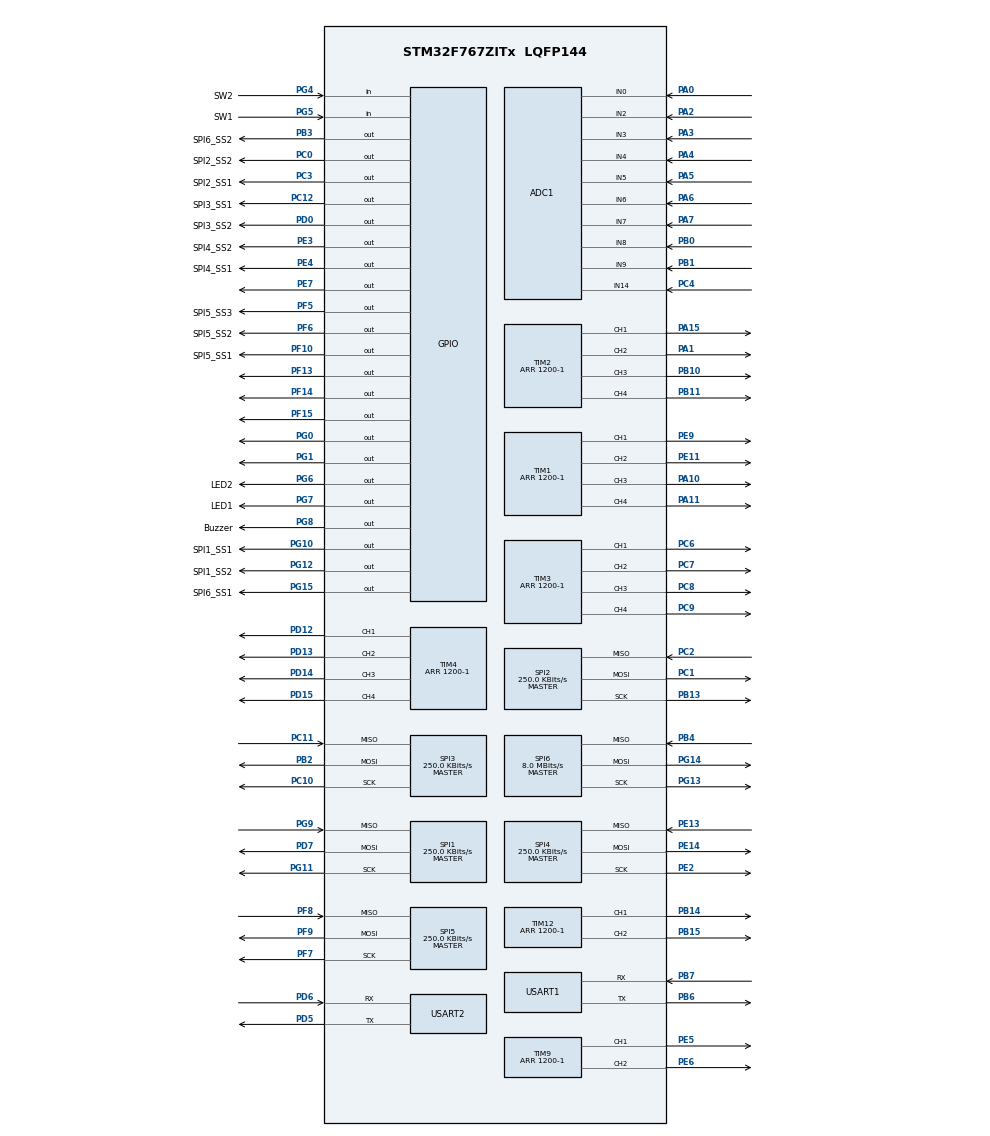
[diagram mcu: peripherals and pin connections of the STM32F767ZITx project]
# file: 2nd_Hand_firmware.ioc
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ADC1.Channel-0\#ChannelRegularConversion=ADC_CHANNEL_0
ADC1.NbrOfConversionFlag=1
ADC1.Rank-0\#ChannelRegularConversion=1
ADC1.SamplingTime-0\#ChannelRegularConversion=ADC_SAMPLETIME_3CYCLES
ADC1.master=1
CORTEX_M7.default_mode_Activation=1
Mcu.Family=STM32F7
Mcu.Name=STM32F767ZITx
Mcu.Package=LQFP144
NVIC.PriorityGroup=NVIC_PRIORITYGROUP_4
NVIC.TIM5_IRQn=true\:0\:0\:false\:false\:true\:true\:true\:true
NVIC.USART1_IRQn=true\:0\:0\:false\:false\:true\:true\:true\:true
PA0/WKUP.Signal=ADCx_IN0
PA1.Signal=S_TIM2_CH2
PA10.Signal=S_TIM1_CH3
PA11.Signal=S_TIM1_CH4
PA13.Mode=Serial_Wire
PA13.Signal=SYS_JTMS-SWDIO
PA14.Mode=Serial_Wire
PA14.Signal=SYS_JTCK-SWCLK
PA15.Signal=S_TIM2_CH1_ETR
PA2.Signal=ADCx_IN2
PA3.Signal=ADCx_IN3
PA4.Signal=ADCx_IN4
PA5.Signal=ADCx_IN5
PA6.Signal=ADCx_IN6
PA7.Signal=ADCx_IN7
PB0.Signal=ADCx_IN8
PB1.Signal=ADCx_IN9
PB10.Signal=S_TIM2_CH3
PB11.Signal=S_TIM2_CH4
PB13.Mode=Full_Duplex_Master
PB13.Signal=SPI2_SCK
PB14.Signal=S_TIM12_CH1
PB15.Signal=S_TIM12_CH2
PB2.Mode=Full_Duplex_Master
PB2.Signal=SPI3_MOSI
PB3.GPIO_Label=SPI6_SS2
PB3.GPIO_PuPd=GPIO_PULLUP
PB3.Signal=GPIO_Output
PB4.Mode=Full_Duplex_Master
PB4.Signal=SPI6_MISO
PB6.Mode=Asynchronous
PB6.Signal=USART1_TX
PB7.Mode=Asynchronous
PB7.Signal=USART1_RX
PC0.GPIO_Label=SPI2_SS2
PC0.GPIO_PuPd=GPIO_PULLUP
PC0.Signal=GPIO_Output
PC1.Mode=Full_Duplex_Master
PC1.Signal=SPI2_MOSI
PC10.Mode=Full_Duplex_Master
PC10.Signal=SPI3_SCK
PC11.Mode=Full_Duplex_Master
PC11.Signal=SPI3_MISO
PC12.GPIO_Label=SPI3_SS1
PC12.GPIO_PuPd=GPIO_PULLUP
PC12.Signal=GPIO_Output
PC14/OSC32_IN.Mode=LSE-External-Oscillator
PC14/OSC32_IN.Signal=RCC_OSC32_IN
PC15/OSC32_OUT.Mode=LSE-External-Oscillator
PC15/OSC32_OUT.Signal=RCC_OSC32_OUT
PC2.Mode=Full_Duplex_Master
PC2.Signal=SPI2_MISO
PC3.GPIO_Label=SPI2_SS1
PC3.GPIO_PuPd=GPIO_PULLUP
PC3.Signal=GPIO_Output
PC4.Signal=ADCx_IN14
PC6.Signal=S_TIM3_CH1
PC7.Signal=S_TIM3_CH2
PC8.Signal=S_TIM3_CH3
PC9.Signal=S_TIM3_CH4
PD0.GPIO_Label=SPI3_SS2
PD0.GPIO_PuPd=GPIO_PULLUP
PD0.Signal=GPIO_Output
PD12.Signal=S_TIM4_CH1
PD13.Signal=S_TIM4_CH2
PD14.Signal=S_TIM4_CH3
PD15.Signal=S_TIM4_CH4
PD5.Mode=Asynchronous
PD5.Signal=USART2_TX
PD6.Mode=Asynchronous
PD6.Signal=USART2_RX
PD7.Mode=Full_Duplex_Master
PD7.Signal=SPI1_MOSI
PE11.Signal=S_TIM1_CH2
PE13.Mode=Full_Duplex_Master
PE13.Signal=SPI4_MISO
PE14.Mode=Full_Duplex_Master
PE14.Signal=SPI4_MOSI
PE2.Mode=Full_Duplex_Master
PE2.Signal=SPI4_SCK
PE3.GPIO_Label=SPI4_SS2
PE3.GPIO_PuPd=GPIO_PULLUP
PE3.Signal=GPIO_Output
PE4.GPIO_Label=SPI4_SS1
PE4.GPIO_PuPd=GPIO_PULLUP
PE4.Signal=GPIO_Output
PE5.Signal=S_TIM9_CH1
PE6.Signal=S_TIM9_CH2
PE7.Signal=GPIO_Output
PE9.Signal=S_TIM1_CH1
PF10.GPIO_Label=SPI5_SS1
PF10.GPIO_PuPd=GPIO_PULLUP
PF10.Signal=GPIO_Output
PF13.Signal=GPIO_Output
PF14.Signal=GPIO_Output
PF15.Signal=GPIO_Output
PF5.GPIO_Label=SPI5_SS3
PF5.GPIO_PuPd=GPIO_PULLUP
PF5.Signal=GPIO_Output
PF6.GPIO_Label=SPI5_SS2
PF6.GPIO_PuPd=GPIO_PULLUP
PF6.Signal=GPIO_Output
PF7.Mode=Full_Duplex_Master
PF7.Signal=SPI5_SCK
PF8.Mode=Full_Duplex_Master
PF8.Signal=SPI5_MISO
PF9.Mode=Full_Duplex_Master
PF9.Signal=SPI5_MOSI
PG0.Signal=GPIO_Output
PG1.Signal=GPIO_Output
PG10.GPIO_Label=SPI1_SS1
PG10.GPIO_PuPd=GPIO_PULLUP
PG10.Signal=GPIO_Output
PG11.Mode=Full_Duplex_Master
PG11.Signal=SPI1_SCK
PG12.GPIO_Label=SPI1_SS2
PG12.GPIO_PuPd=GPIO_PULLUP
PG12.Signal=GPIO_Output
PG13.Mode=Full_Duplex_Master
PG13.Signal=SPI6_SCK
PG14.Mode=Full_Duplex_Master
PG14.Signal=SPI6_MOSI
PG15.GPIO_Label=SPI6_SS1
PG15.GPIO_PuPd=GPIO_PULLUP
PG15.Signal=GPIO_Output
PG4.GPIO_Label=SW2
PG4.GPIO_PuPd=GPIO_PULLUP
PG4.Signal=GPIO_Input
PG5.GPIO_Label=SW1
PG5.GPIO_PuPd=GPIO_PULLUP
PG5.Signal=GPIO_Input
PG6.GPIO_Label=LED2
PG6.Signal=GPIO_Output
PG7.GPIO_Label=LED1
PG7.Signal=GPIO_Output
PG8.GPIO_Label=Buzzer
PG8.Signal=GPIO_Output
PG9.Mode=Full_Duplex_Master
PG9.Signal=SPI1_MISO
PH0/OSC_IN.Mode=HSE-External-Oscillator
PH0/OSC_IN.Signal=RCC_OSC_IN
PH1/OSC_OUT.Mode=HSE-External-Oscillator
PH1/OSC_OUT.Signal=RCC_OSC_OUT
ProjectManager.HeapSize=0x200
ProjectManager.StackSize=0x400
ProjectManager.TargetToolchain=CMake
RCC.HSE_VALUE=25000000
RCC.HSI_VALUE=16000000
RCC.USBFreq_Value=96000000
RCC.VCOOutputFreq_Value=192000000
SH.ADCx_IN0.0=ADC1_IN0,IN0
SH.ADCx_IN14.0=ADC1_IN14,IN14
SH.ADCx_IN2.0=ADC1_IN2,IN2
SH.ADCx_IN3.0=ADC1_IN3,IN3
SH.ADCx_IN4.0=ADC1_IN4,IN4
SH.ADCx_IN5.0=ADC1_IN5,IN5
SH.ADCx_IN6.0=ADC1_IN6,IN6
SH.ADCx_IN7.0=ADC1_IN7,IN7
SH.ADCx_IN8.0=ADC1_IN8,IN8
SH.ADCx_IN9.0=ADC1_IN9,IN9
SH.S_TIM12_CH1.0=TIM12_CH1,PWM Generation1 CH1
SH.S_TIM12_CH2.0=TIM12_CH2,PWM Generation2 CH2
SH.S_TIM1_CH1.0=TIM1_CH1,PWM Generation1 CH1
SH.S_TIM1_CH2.0=TIM1_CH2,PWM Generation2 CH2
SH.S_TIM1_CH3.0=TIM1_CH3,PWM Generation3 CH3
SH.S_TIM1_CH4.0=TIM1_CH4,PWM Generation4 CH4
SH.S_TIM2_CH1_ETR.0=TIM2_CH1,PWM Generation1 CH1
SH.S_TIM2_CH2.0=TIM2_CH2,PWM Generation2 CH2
SH.S_TIM2_CH3.0=TIM2_CH3,PWM Generation3 CH3
SH.S_TIM2_CH4.0=TIM2_CH4,PWM Generation4 CH4
SH.S_TIM3_CH1.0=TIM3_CH1,PWM Generation1 CH1
SH.S_TIM3_CH2.0=TIM3_CH2,PWM Generation2 CH2
SH.S_TIM3_CH3.0=TIM3_CH3,PWM Generation3 CH3
SH.S_TIM3_CH4.0=TIM3_CH4,PWM Generation4 CH4
SH.S_TIM4_CH1.0=TIM4_CH1,PWM Generation1 CH1
SH.S_TIM4_CH2.0=TIM4_CH2,PWM Generation2 CH2
SH.S_TIM4_CH3.0=TIM4_CH3,PWM Generation3 CH3
SH.S_TIM4_CH4.0=TIM4_CH4,PWM Generation4 CH4
SH.S_TIM9_CH1.0=TIM9_CH1,PWM Generation1 CH1
SH.S_TIM9_CH2.0=TIM9_CH2,PWM Generation2 CH2
SPI1.BaudRatePrescaler=SPI_BAUDRATEPRESCALER_64
SPI1.CLKPhase=SPI_PHASE_1EDGE
SPI1.CalculateBaudRate=250.0 KBits/s
SPI1.DataSize=SPI_DATASIZE_8BIT
SPI1.Direction=SPI_DIRECTION_2LINES
SPI1.Mode=SPI_MODE_MASTER
SPI1.NSSPMode=SPI_NSS_PULSE_DISABLE
SPI1.VirtualType=VM_MASTER
SPI2.BaudRatePrescaler=SPI_BAUDRATEPRESCALER_64
SPI2.CLKPhase=SPI_PHASE_1EDGE
SPI2.CalculateBaudRate=250.0 KBits/s
SPI2.DataSize=SPI_DATASIZE_8BIT
SPI2.Direction=SPI_DIRECTION_2LINES
SPI2.Mode=SPI_MODE_MASTER
SPI2.NSSPMode=SPI_NSS_PULSE_DISABLE
SPI2.VirtualType=VM_MASTER
SPI3.BaudRatePrescaler=SPI_BAUDRATEPRESCALER_64
SPI3.CLKPhase=SPI_PHASE_1EDGE
SPI3.CalculateBaudRate=250.0 KBits/s
SPI3.DataSize=SPI_DATASIZE_8BIT
SPI3.Direction=SPI_DIRECTION_2LINES
SPI3.Mode=SPI_MODE_MASTER
SPI3.NSSPMode=SPI_NSS_PULSE_DISABLE
SPI3.VirtualType=VM_MASTER
SPI4.BaudRatePrescaler=SPI_BAUDRATEPRESCALER_64
SPI4.CLKPhase=SPI_PHASE_2EDGE
SPI4.CalculateBaudRate=250.0 KBits/s
SPI4.DataSize=SPI_DATASIZE_16BIT
SPI4.Direction=SPI_DIRECTION_2LINES
SPI4.Mode=SPI_MODE_MASTER
SPI4.VirtualType=VM_MASTER
SPI5.BaudRatePrescaler=SPI_BAUDRATEPRESCALER_64
SPI5.CLKPhase=SPI_PHASE_1EDGE
SPI5.CalculateBaudRate=250.0 KBits/s
SPI5.DataSize=SPI_DATASIZE_8BIT
SPI5.Direction=SPI_DIRECTION_2LINES
SPI5.Mode=SPI_MODE_MASTER
SPI5.NSSPMode=SPI_NSS_PULSE_DISABLE
SPI5.VirtualType=VM_MASTER
SPI6.BaudRatePrescaler=SPI_BAUDRATEPRESCALER_2
SPI6.CalculateBaudRate=8.0 MBits/s
SPI6.DataSize=SPI_DATASIZE_4BIT
SPI6.Direction=SPI_DIRECTION_2LINES
SPI6.Mode=SPI_MODE_MASTER
SPI6.VirtualType=VM_MASTER
TIM1.Channel-PWM\ Generation1\ CH1=TIM_CHANNEL_1
TIM1.Channel-PWM\ Generation2\ CH2=TIM_CHANNEL_2
TIM1.Channel-PWM\ Generation3\ CH3=TIM_CHANNEL_3
TIM1.Channel-PWM\ Generation4\ CH4=TIM_CHANNEL_4
TIM1.Period=1200-1
TIM12.Channel-PWM\ Generation1\ CH1=TIM_CHANNEL_1
TIM12.Channel-PWM\ Generation2\ CH2=TIM_CHANNEL_2
TIM12.Period=1200-1
TIM2.Channel-PWM\ Generation1\ CH1=TIM_CHANNEL_1
TIM2.Channel-PWM\ Generation2\ CH2=TIM_CHANNEL_2
TIM2.Channel-PWM\ Generation3\ CH3=TIM_CHANNEL_3
TIM2.Channel-PWM\ Generation4\ CH4=TIM_CHANNEL_4
TIM2.Period=1200-1
TIM3.Channel-PWM\ Generation1\ CH1=TIM_CHANNEL_1
TIM3.Channel-PWM\ Generation2\ CH2=TIM_CHANNEL_2
TIM3.Channel-PWM\ Generation3\ CH3=TIM_CHANNEL_3
TIM3.Channel-PWM\ Generation4\ CH4=TIM_CHANNEL_4
TIM3.Period=1200-1
TIM4.Channel-PWM\ Generation1\ CH1=TIM_CHANNEL_1
TIM4.Channel-PWM\ Generation2\ CH2=TIM_CHANNEL_2
TIM4.Channel-PWM\ Generation3\ CH3=TIM_CHANNEL_3
TIM4.Channel-PWM\ Generation4\ CH4=TIM_CHANNEL_4
TIM4.Period=1200-1
TIM5.Period=10000-1
TIM5.Prescaler=96
TIM9.Channel-PWM\ Generation1\ CH1=TIM_CHANNEL_1
TIM9.Channel-PWM\ Generation2\ CH2=TIM_CHANNEL_2
TIM9.Period=1200-1
USART1.VirtualMode-Asynchronous=VM_ASYNC
USART2.VirtualMode-Asynchronous=VM_ASYNC
VP_TIM12_VS_ClockSourceINT.Mode=Internal
VP_TIM1_VS_ClockSourceINT.Mode=Internal
VP_TIM2_VS_ClockSourceINT.Mode=Internal
VP_TIM3_VS_ClockSourceINT.Mode=Internal
VP_TIM4_VS_ClockSourceINT.Mode=Internal
VP_TIM5_VS_ClockSourceINT.Mode=Internal
VP_TIM9_VS_ClockSourceINT.Mode=Internal
board=custom

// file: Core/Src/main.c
/* USER CODE BEGIN Header */
/**
  ******************************************************************************
  * @file           : main.c
  * @brief          : Main program body
  ******************************************************************************
  * @attention
  *
  * Copyright (c) 2025 STMicroelectronics.
  * All rights reserved.
  *
  * This software is licensed under terms that can be found in the LICENSE file
  * in the root directory of this software component.
  * If no LICENSE file comes with this software, it is provided AS-IS.
  *
  ******************************************************************************
  */
/* USER CODE END Header */
#include "main.h"
#include "adc.h"
#include "spi.h"
#include "tim.h"
#include "usart.h"
#include "gpio.h"

/* USER CODE BEGIN Includes */
#include "alt-main.h"
#include <stdio.h>
/* USER CODE END Includes */

void SystemClock_Config(void);
static void MPU_Config(void);

/* USER CODE BEGIN 0 */
int __io_putchar(int ch)
{
    // UART1でprintf出力
    HAL_UART_Transmit(&huart1, (uint8_t *)&ch, 1, HAL_MAX_DELAY);
    return ch;
}

/* USER CODE END 0 */

int main(void)
{

  /* MPU Configuration--------------------------------------------------------*/
  MPU_Config();

  /* MCU Configuration--------------------------------------------------------*/

  /* Reset of all peripherals, Initializes the Flash interface and the Systick. */
  HAL_Init();

  /* Configure the system clock */
  SystemClock_Config();

  /* Initialize all configured peripherals */
  MX_GPIO_Init();
  MX_ADC1_Init();
  MX_SPI1_Init();
  MX_SPI2_Init();
  MX_SPI3_Init();
  MX_SPI4_Init();
  MX_SPI5_Init();
  MX_SPI6_Init();
  MX_TIM1_Init();
  MX_TIM2_Init();
  MX_TIM3_Init();
  MX_TIM4_Init();
  MX_TIM9_Init();
  MX_TIM12_Init();
  MX_USART1_UART_Init();
  MX_USART2_UART_Init();
  MX_TIM5_Init();
  /* USER CODE BEGIN 2 */
  alt_setup();
  alt_main();

  /* USER CODE END 2 */

  /* Infinite loop */
  /* USER CODE BEGIN WHILE */
  while (1)
  {
    alt_loop();
    /* USER CODE END WHILE */

  }
}

void SystemClock_Config(void)
{
  RCC_OscInitTypeDef RCC_OscInitStruct = {0};
  RCC_ClkInitTypeDef RCC_ClkInitStruct = {0};

  /** Configure LSE Drive Capability
  */
  HAL_PWR_EnableBkUpAccess();

  /** Configure the main internal regulator output voltage
  */
  __HAL_RCC_PWR_CLK_ENABLE();
  __HAL_PWR_VOLTAGESCALING_CONFIG(PWR_REGULATOR_VOLTAGE_SCALE3);

  /** Initializes the RCC Oscillators according to the specified parameters
  * in the RCC_OscInitTypeDef structure.
  */
  RCC_OscInitStruct.OscillatorType = RCC_OSCILLATORTYPE_HSI;
  RCC_OscInitStruct.HSIState = RCC_HSI_ON;
  RCC_OscInitStruct.HSICalibrationValue = RCC_HSICALIBRATION_DEFAULT;
  RCC_OscInitStruct.PLL.PLLState = RCC_PLL_NONE;
  if (HAL_RCC_OscConfig(&RCC_OscInitStruct) != HAL_OK)
  {
    Error_Handler();
  }

  /** Initializes the CPU, AHB and APB buses clocks
  */
  RCC_ClkInitStruct.ClockType = RCC_CLOCKTYPE_HCLK|RCC_CLOCKTYPE_SYSCLK
                              |RCC_CLOCKTYPE_PCLK1|RCC_CLOCKTYPE_PCLK2;
  RCC_ClkInitStruct.SYSCLKSource = RCC_SYSCLKSOURCE_HSI;
  RCC_ClkInitStruct.AHBCLKDivider = RCC_SYSCLK_DIV1;
  RCC_ClkInitStruct.APB1CLKDivider = RCC_HCLK_DIV1;
  RCC_ClkInitStruct.APB2CLKDivider = RCC_HCLK_DIV1;

  if (HAL_RCC_ClockConfig(&RCC_ClkInitStruct, FLASH_LATENCY_0) != HAL_OK)
  {
    Error_Handler();
  }
}

 /* MPU Configuration */

void MPU_Config(void)
{
  MPU_Region_InitTypeDef MPU_InitStruct = {0};

  /* Disables the MPU */
  HAL_MPU_Disable();

  /** Initializes and configures the Region and the memory to be protected
  */
  MPU_InitStruct.Enable = MPU_REGION_ENABLE;
  MPU_InitStruct.Number = MPU_REGION_NUMBER0;
  MPU_InitStruct.BaseAddress = 0x0;
  MPU_InitStruct.Size = MPU_REGION_SIZE_4GB;
  MPU_InitStruct.SubRegionDisable = 0x87;
  MPU_InitStruct.TypeExtField = MPU_TEX_LEVEL0;
  MPU_InitStruct.AccessPermission = MPU_REGION_NO_ACCESS;
  MPU_InitStruct.DisableExec = MPU_INSTRUCTION_ACCESS_DISABLE;
  MPU_InitStruct.IsShareable = MPU_ACCESS_SHAREABLE;
  MPU_InitStruct.IsCacheable = MPU_ACCESS_NOT_CACHEABLE;
  MPU_InitStruct.IsBufferable = MPU_ACCESS_NOT_BUFFERABLE;

  HAL_MPU_ConfigRegion(&MPU_InitStruct);
  /* Enables the MPU */
  HAL_MPU_Enable(MPU_PRIVILEGED_DEFAULT);

}

void Error_Handler(void)
{
  __disable_irq();
  while (1)
  {
  }
}
